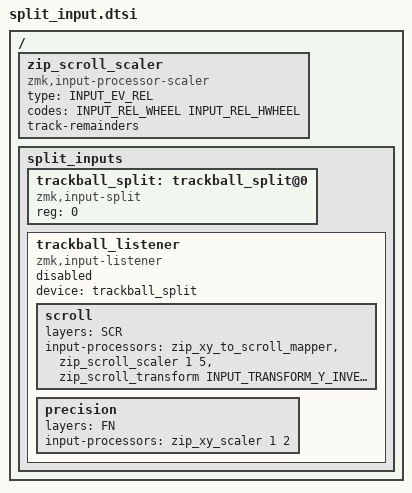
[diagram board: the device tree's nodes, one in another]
#include <dt-bindings/zmk/input_transform.h>
#include <input/processors.dtsi>

#define DEF 0
#define NAV 1
#define FN 2
#define NUM 3
#define SYS 4
#define MOUSE 5
#define SCR 6

/ {
    zip_scroll_scaler: zip_scroll_scaler {
        compatible = "zmk,input-processor-scaler";
        #input-processor-cells = <2>;
        type = <INPUT_EV_REL>;
        codes = <INPUT_REL_WHEEL INPUT_REL_HWHEEL>;
        track-remainders;
    };

    // zip_y_to_scroll_mapper: zip_y_to_scroll_mapper {
    //     compatible = "zmk,input-processor-code-mapper";
    //     #input-processor-cells = <0>;
    //     type = <INPUT_EV_REL>;
    //     map = <INPUT_REL_Y INPUT_REL_WHEEL>;
    // };

    split_inputs {
        #address-cells = <1>;
        #size-cells = <0>;
    
        trackball_split: trackball_split@0 {
            compatible = "zmk,input-split";
            reg = <0>;
        };
    
        trackball_listener: trackball_listener {
            compatible = "zmk,input-listener";
            status = "disabled";
            device = <&trackball_split>;

            scroll {
                layers = <SCR>;
                input-processors = <&zip_xy_to_scroll_mapper>, <&zip_scroll_scaler 1 5>, <&zip_scroll_transform INPUT_TRANSFORM_Y_INVERT>;
            };
        
            precision {
                layers = <FN>;
                input-processors = <&zip_xy_scaler 1 2>;
            };
        };
    };
};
